# ESP32-S2 register map
Vendor: ESPRESSIF SYSTEMS (SHANGHAI) CO., LTD.; Series: ESP32 S-Series; File version: 20
CPU: Xtensa LX7 r0p0, little endian, no MPU, no FPU, 0 interrupt priority bits
Address unit: 32 bits
Registers are 32-bit, read-write, reset 0x0 unless marked. A register's access mark holds for its fields unless they carry their own. Offsets are from the block's base; [hi:lo] are bit positions.

## CRYPTO_DMA — Crypto DMA Controller
Base 0x6003F000
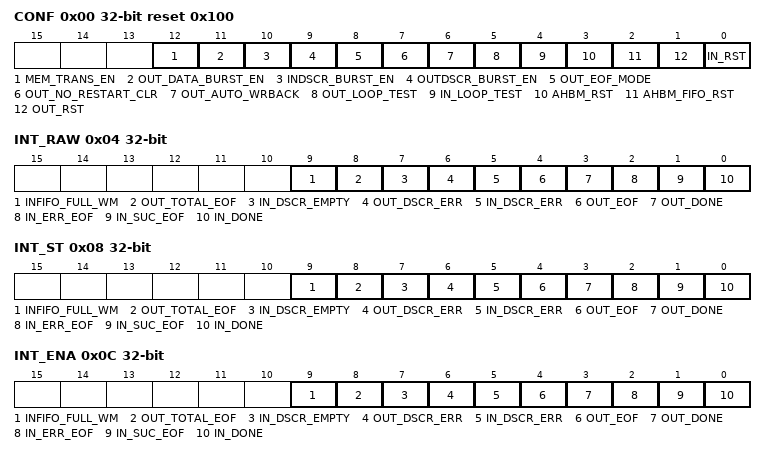
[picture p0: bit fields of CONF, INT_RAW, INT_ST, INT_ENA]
0x00 CONF reset 0x100 — DMA configuration register
  [12] MEM_TRANS_EN — Set this bit to enable automatic transmitting data from memory to memory via DMA.
  [11] OUT_DATA_BURST_EN — Set this bit to enable INCR burst transfer when TX FIFO reads data from internal RAM.
  [10] INDSCR_BURST_EN — Set this bit to enable INCR burst transfer when RX FIFO reads descriptor from internal RAM.
  [9] OUTDSCR_BURST_EN — Set this bit to enable INCR burst transfer when TX FIFO reads descriptor from internal RAM.
  [8] OUT_EOF_MODE — Out EOF flag generation mode of TX FIFO. 1: EOF flag of TX is generated when the last data with EOF would be transmitted has been popped from FIFO of Crypto DMA; 0: EOF flag is generated when the last data with EOF would be transmitted has been pushed into FIFO of Crypto DMA.
    0=ON_PUSH (EOF flag is generated when the last data with EOF would be transmitted has been pushed into FIFO of Crypto DMA); 1=ON_POP (EOF flag is generated when the last data with EOF would be transmitted has been popped from FIFO of Crypto DMA)
  [7] OUT_NO_RESTART_CLR — Reserved
  [6] OUT_AUTO_WRBACK — Set this bit to enable automatic outlink-writeback when all the data in TX Buffer has been transmitted.
  [5] OUT_LOOP_TEST — Reserved
  [4] IN_LOOP_TEST — Reserved
  [3] AHBM_RST — Reset crypto DMA AHB master.
  [2] AHBM_FIFO_RST — This bit is used to reset crypto DMA AHB master FIFO pointer.
  [1] OUT_RST — This bit is used to reset crypto DMA out FSM and TX FIFO pointer.
  [0] IN_RST — This bit is used to reset crypto DMA in FSM and RX FIFO pointer.
0x04 INT_RAW ro — Raw interrupt status
  [9] INFIFO_FULL_WM — Set when received data byte number is up to threshold configured by CRYPTO_DMA_INFIFO_FULL_THRS in RX FIFO.
  [8] OUT_TOTAL_EOF — Set when data corresponding to all transmit descriptor and the last descriptor with valid EOF is transmitted out.
  [7] IN_DSCR_EMPTY — Set when receiving data is completed and no more receive descriptor.
  [6] OUT_DSCR_ERR — Set when detecting transmit descriptor error, including owner error, the second and third word error of transmit descriptor.
  [5] IN_DSCR_ERR — Set when detecting receive descriptor error, including owner error, the second and third word error of receive descriptor.
  [4] OUT_EOF — Set when Out EOF flag is generated.
  [3] OUT_DONE — Set when all data indicated by one transmit descriptor has been pushed into TX FIFO.
  [2] IN_ERR_EOF — Reserved
  [1] IN_SUC_EOF — Set when the last data of one frame is received by Crypto DMA RX FIFO.
  [0] IN_DONE — Set when the last data of one frame is received or the receive buffer is full indicated by receive descriptor.
0x08 INT_ST ro — Masked interrupt status
  [9] INFIFO_FULL_WM — The masked interrupt status bit for the INFIFO_FULL_WM interrupt.
  [8] OUT_TOTAL_EOF — The masked interrupt status bit for the OUT_TOTAL_EOF interrupt.
  [7] IN_DSCR_EMPTY — The masked interrupt status bit for the IN_DSCR_EMPTY interrupt.
  [6] OUT_DSCR_ERR — The masked interrupt status bit for the OUT_DSCR_ERR interrupt.
  [5] IN_DSCR_ERR — The masked interrupt status bit for the IN_DSCR_ERR interrupt.
  [4] OUT_EOF — The masked interrupt status bit for the OUT_EOF interrupt.
  [3] OUT_DONE — The masked interrupt status bit for the OUT_DONE interrupt.
  [2] IN_ERR_EOF — The masked interrupt status bit for the IN_ERR_EOF interrupt.
  [1] IN_SUC_EOF — The masked interrupt status bit for the IN_SUC_EOF interrupt.
  [0] IN_DONE — The masked interrupt status bit for the IN_DONE interrupt.
0x0C INT_ENA — Interrupt enable bits
  [9] INFIFO_FULL_WM — The interrupt enable bit for the INFIFO_FULL_WM interrupt.
  [8] OUT_TOTAL_EOF — The interrupt enable bit for the OUT_TOTAL_EOF interrupt.
  [7] IN_DSCR_EMPTY — The interrupt enable bit for the IN_DSCR_EMPTY interrupt.
  [6] OUT_DSCR_ERR — The interrupt enable bit for the OUT_DSCR_ERR interrupt.
  [5] IN_DSCR_ERR — The interrupt enable bit for the IN_DSCR_ERR interrupt.
  [4] OUT_EOF — The interrupt enable bit for the OUT_EOF interrupt.
  [3] OUT_DONE — The interrupt enable bit for the OUT_DONE interrupt.
  [2] IN_ERR_EOF — The interrupt enable bit for the IN_ERR_EOF interrupt.
  [1] IN_SUC_EOF — The interrupt enable bit for the IN_SUC_EOF interrupt.
  [0] IN_DONE — The interrupt enable bit for the IN_DONE interrupt.
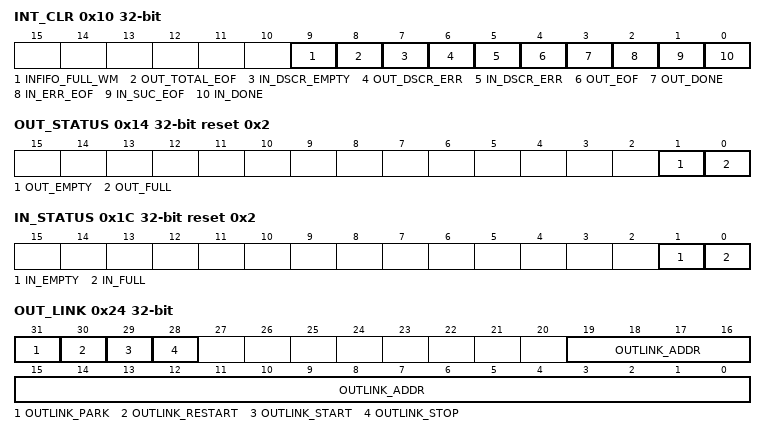
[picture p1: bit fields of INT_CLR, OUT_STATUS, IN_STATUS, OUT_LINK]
0x10 INT_CLR wo — Interrupt clear bits
  [9] INFIFO_FULL_WM write-1-clears — Set this bit to clear the INFIFO_FULL_WM interrupt.
  [8] OUT_TOTAL_EOF write-1-clears — Set this bit to clear the OUT_TOTAL_EOF interrupt.
  [7] IN_DSCR_EMPTY write-1-clears — Set this bit to clear the IN_DSCR_EMPTY interrupt.
  [6] OUT_DSCR_ERR write-1-clears — Set this bit to clear the OUT_DSCR_ERR interrupt.
  [5] IN_DSCR_ERR write-1-clears — Set this bit to clear the IN_DSCR_ERR interrupt.
  [4] OUT_EOF write-1-clears — Set this bit to clear the OUT_EOF interrupt.
  [3] OUT_DONE write-1-clears — Set this bit to clear the OUT_DONE interrupt.
  [2] IN_ERR_EOF write-1-clears — Set this bit to clear the IN_ERR_EOF interrupt.
  [1] IN_SUC_EOF write-1-clears — Set this bit to clear the IN_SUC_EOF interrupt.
  [0] IN_DONE write-1-clears — Set this bit to clear the IN_DONE interrupt.
0x14 OUT_STATUS ro reset 0x2 — TX FIFO status register
  [1] OUT_EMPTY — DMA TX FIFO is empty.
  [0] OUT_FULL — DMA TX FIFO is full.
0x1C IN_STATUS ro reset 0x2 — RX FIFO status register
  [1] IN_EMPTY — DMA RX FIFO is empty.
  [0] IN_FULL — DMA RX FIFO is full.
0x24 OUT_LINK — Link descriptor address and control
  [31] OUTLINK_PARK ro — 1: the transmit descriptor’s FSM is in idle state. 0: the transmit descriptor’s FSM is working.
    0=WORKING (The transmit descriptor’s FSM is working); 1=IDLE (The transmit descriptor’s FSM is in idle state)
  [30] OUTLINK_RESTART — Set this bit to restart a new outlink from the last address.
  [29] OUTLINK_START — Set this bit to enable DMA to read transmit descriptors.
  [28] OUTLINK_STOP — Set this bit to stop DMA from reading transmit descriptors after finishing the current data transaction.
  [19:0] OUTLINK_ADDR — This register stores the 20 least significant bits of the first transmit descriptor’s address.
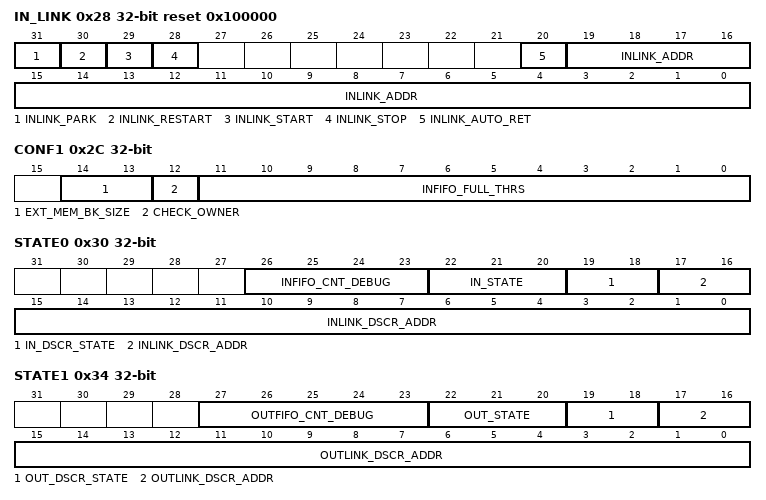
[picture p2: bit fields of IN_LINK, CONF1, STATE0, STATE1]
0x28 IN_LINK reset 0x100000 — Link descriptor address and control
  [31] INLINK_PARK ro — 1: the receive descriptor’s FSM is in idle state. 0: the receive descriptor’s FSM is working.
    0=WORKING (The receive descriptor’s FSM is working); 1=IDLE (The receive descriptor’s FSM is in idle state)
  [30] INLINK_RESTART — Set this bit to mount a new receive descriptor.
  [29] INLINK_START — Set this bit to enable DMA to read receive descriptors.
  [28] INLINK_STOP — Set this bit to stop DMA from reading receive descriptors after finishing the current data transaction.
  [20] INLINK_AUTO_RET — Reserved
  [19:0] INLINK_ADDR — This register stores the 20 least significant bits of the first receive descriptor’s address.
0x2C CONF1 — DMA configuration register
  [14:13] EXT_MEM_BK_SIZE — DMA access external memory block size. 0: 16 bytes; 1: 32 bytes; 2: 64 bytes; 3:Reserved.
    0=SIZE_16 (DMA access external memory block size is 16 bytes); 1=SIZE_32 (DMA access external memory block size is 32 bytes); 2=SIZE_64 (DMA access external memory block size is 64 bytes)
  [12] CHECK_OWNER — Set this bit to enable checking the owner attribute of the link descriptor.
  [11:0] INFIFO_FULL_THRS — This register is used to generate the CRYPTO_DMA_INFIFO_FULL_WM_INT interrupt when the byte number is up to the value of the register.
0x30 STATE0 ro — Status register of receiving data
  [26:23] INFIFO_CNT_DEBUG — This register stores the byte number of the data in the receive descriptor’s FIFO.
  [22:20] IN_STATE — Reserved
  [19:18] IN_DSCR_STATE — Reserved
  [17:0] INLINK_DSCR_ADDR — This register stores the current receive descriptor’s address.
0x34 STATE1 ro — Status register of transmitting data
  [27:23] OUTFIFO_CNT_DEBUG — This register stores the byte number of the data in the transmit descriptor’s FIFO.
  [22:20] OUT_STATE — Reserved
  [19:18] OUT_DSCR_STATE — Reserved
  [17:0] OUTLINK_DSCR_ADDR — This register stores the current transmit descriptor’s address.
0x38 OUT_EOF_DES_ADDR ro — Transmit descriptor address when EOF occurs
  [31:0] OUT_EOF_DES_ADDR — This register stores the address of the transmit descriptor when the EOF bit in this descriptor is 1.
0x3C IN_SUC_EOF_DES_ADDR ro — Receive descriptor address when EOF occurs
  [31:0] IN_SUC_EOF_DES_ADDR — This register stores the address of the receive descriptor when received successful EOF.
0x40 IN_ERR_EOF_DES_ADDR ro — Receive descriptor address when errors occur
  [31:0] IN_ERR_EOF_DES_ADDR — This register stores the address of the receive descriptor when there are some errors in this descriptor.
0x44 OUT_EOF_BFR_DES_ADDR ro — Transmit descriptor address before the last transmit descriptor
  [31:0] OUT_EOF_BFR_DES_ADDR — This register stores the address of the transmit descriptor before the last transmit descriptor.
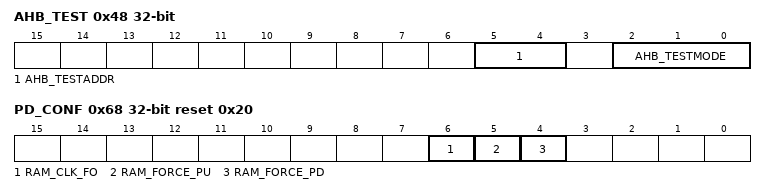
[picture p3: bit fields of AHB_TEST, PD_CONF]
0x48 AHB_TEST
  [5:4] AHB_TESTADDR — Reserved
  [2:0] AHB_TESTMODE — Reserved
0x4C DMA_IN_DSCR ro — Address of current receive descriptor
  [31:0] DMA_IN_DSCR — Address of the current receive descriptor x.
0x50 DMA_IN_DSCR_BF0 ro — Address of last receive descriptor
  [31:0] DMA_IN_DSCR_BF0 — Address of the last receive descriptor x-1.
0x58 DMA_OUT_DSCR ro — Address of current transmit descriptor
  [31:0] DMA_OUT_DSCR — Address of the current transmit descriptor y.
0x5C DMA_OUT_DSCR_BF0 ro — Address of last transmit descriptor
  [31:0] DMA_OUT_DSCR_BF0 — Address of the last transmit descriptor y-1.
0x64 AES_SHA_SELECT
  [0] SELECT — Select one between AES and SHA to use DMA. 0: AES. 1: SHA.
    0=AES (The AES peripheral uses the Crypto DMA); 1=SHA (The SHA peripheral uses the Crypto DMA)
0x68 PD_CONF reset 0x20 — Power control register
  [6] RAM_CLK_FO — 1: Force to open the clock and bypass the gate-clock when accessing the RAM in DMA. 0: A gate-clock will be used when accessing the RAM in DMA.
  [5] RAM_FORCE_PU — Force power up signal to RAM. 0: only when CRYPTO_DMA_RAM_FORCE_PD is 1, power down RAM; 1: force RAM power up.
  [4] RAM_FORCE_PD — Force power down signal to RAM. 0: force RAM power up; 1: only when CRYPTO_DMA_RAM_FORCE_PU is 0, power down RAM.
0xFC DATE — Crypto DMA version control register
